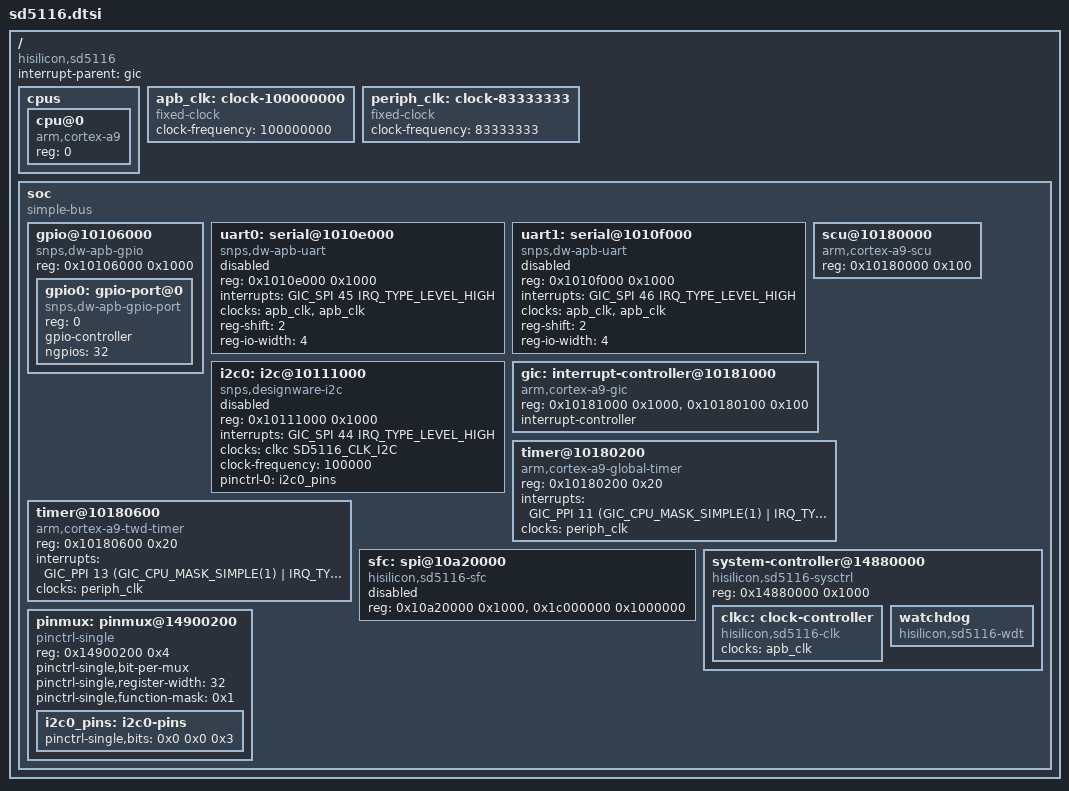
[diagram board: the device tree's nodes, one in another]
// SPDX-License-Identifier: GPL-2.0-or-later OR MIT
/*
 * HiSilicon SD5116 GPON SoC
 *
 * Copyright (c) 2026 Mario Moura <mm@mariomoura.com>
 */

#include <dt-bindings/clock/hisilicon,sd5116-clock.h>
#include <dt-bindings/interrupt-controller/arm-gic.h>

/ {
	compatible = "hisilicon,sd5116";
	interrupt-parent = <&gic>;
	#address-cells = <1>;
	#size-cells = <1>;

	cpus {
		#address-cells = <1>;
		#size-cells = <0>;

		cpu@0 {
			device_type = "cpu";
			compatible = "arm,cortex-a9";
			reg = <0>;
		};
	};

	apb_clk: clock-100000000 {
		compatible = "fixed-clock";
		#clock-cells = <0>;
		clock-frequency = <100000000>;
	};

	/* Cortex-A9 PERIPHCLK, feeds the global and TWD timers */
	periph_clk: clock-83333333 {
		compatible = "fixed-clock";
		#clock-cells = <0>;
		clock-frequency = <83333333>;
	};

	soc {
		compatible = "simple-bus";
		#address-cells = <1>;
		#size-cells = <1>;
		ranges;

		gpio@10106000 {
			compatible = "snps,dw-apb-gpio";
			reg = <0x10106000 0x1000>;
			#address-cells = <1>;
			#size-cells = <0>;

			gpio0: gpio-port@0 {
				compatible = "snps,dw-apb-gpio-port";
				reg = <0>;
				gpio-controller;
				#gpio-cells = <2>;
				ngpios = <32>;
			};
		};

		uart0: serial@1010e000 {
			compatible = "snps,dw-apb-uart";
			reg = <0x1010e000 0x1000>;
			interrupts = <GIC_SPI 45 IRQ_TYPE_LEVEL_HIGH>;
			clocks = <&apb_clk>, <&apb_clk>;
			clock-names = "baudclk", "apb_pclk";
			reg-shift = <2>;
			reg-io-width = <4>;
			status = "disabled";
		};

		uart1: serial@1010f000 {
			compatible = "snps,dw-apb-uart";
			reg = <0x1010f000 0x1000>;
			interrupts = <GIC_SPI 46 IRQ_TYPE_LEVEL_HIGH>;
			clocks = <&apb_clk>, <&apb_clk>;
			clock-names = "baudclk", "apb_pclk";
			reg-shift = <2>;
			reg-io-width = <4>;
			status = "disabled";
		};

		i2c0: i2c@10111000 {
			compatible = "snps,designware-i2c";
			reg = <0x10111000 0x1000>;
			interrupts = <GIC_SPI 44 IRQ_TYPE_LEVEL_HIGH>;
			clocks = <&clkc SD5116_CLK_I2C>;
			clock-frequency = <100000>;
			pinctrl-names = "default";
			pinctrl-0 = <&i2c0_pins>;
			#address-cells = <1>;
			#size-cells = <0>;
			status = "disabled";
		};

		scu@10180000 {
			compatible = "arm,cortex-a9-scu";
			reg = <0x10180000 0x100>;
		};

		gic: interrupt-controller@10181000 {
			compatible = "arm,cortex-a9-gic";
			reg = <0x10181000 0x1000>,
			      <0x10180100 0x100>;
			#interrupt-cells = <3>;
			interrupt-controller;
		};

		timer@10180200 {
			compatible = "arm,cortex-a9-global-timer";
			reg = <0x10180200 0x20>;
			interrupts = <GIC_PPI 11 (GIC_CPU_MASK_SIMPLE(1) | IRQ_TYPE_EDGE_RISING)>;
			clocks = <&periph_clk>;
		};

		timer@10180600 {
			compatible = "arm,cortex-a9-twd-timer";
			reg = <0x10180600 0x20>;
			interrupts = <GIC_PPI 13 (GIC_CPU_MASK_SIMPLE(1) | IRQ_TYPE_EDGE_RISING)>;
			clocks = <&periph_clk>;
		};

		sfc: spi@10a20000 {
			compatible = "hisilicon,sd5116-sfc";
			reg = <0x10a20000 0x1000>, <0x1c000000 0x1000000>;
			reg-names = "control", "memory";
			#address-cells = <1>;
			#size-cells = <0>;
			status = "disabled";
		};

		system-controller@14880000 {
			compatible = "hisilicon,sd5116-sysctrl", "syscon", "simple-mfd";
			reg = <0x14880000 0x1000>;

			clkc: clock-controller {
				compatible = "hisilicon,sd5116-clk";
				clocks = <&apb_clk>;
				#clock-cells = <1>;
			};

			watchdog {
				compatible = "hisilicon,sd5116-wdt";
			};
		};

		pinmux: pinmux@14900200 {
			compatible = "pinctrl-single";
			reg = <0x14900200 0x4>;
			#pinctrl-cells = <2>;
			pinctrl-single,bit-per-mux;
			pinctrl-single,register-width = <32>;
			pinctrl-single,function-mask = <0x1>;

			/* SCL and SDA: 0 selects I2C, 1 GPIO */
			i2c0_pins: i2c0-pins {
				pinctrl-single,bits = <0x0 0x0 0x3>;
			};
		};
	};
};
